# RL6955_IP_SVD register map
Vendor: Realtek
Registers are 32-bit, read-write, reset 0x0 unless marked. A register's access mark holds for its fields unless they carry their own. Offsets are from the block's base; [hi:lo] are bit positions; {n}, {i} and the like mark numbered series.

## UARTLOG_REG
Base 0x41005000
0x00 UART_DLL — UART divisor length register
  [7:0] baud — The low 8 bits of divisor coefficient (not used)
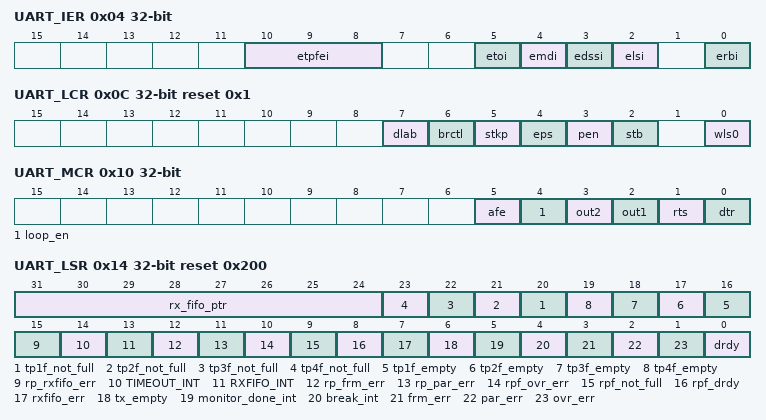
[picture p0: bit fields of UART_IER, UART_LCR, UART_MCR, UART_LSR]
0x04 UART_IER — UART interrupt enable register
  [10:8] etpfei — Tx Path FIFO Empty interrupt (ETPFEI) (Tx Path FIFO empty) enable control *000: All Tx Path FIFO empty interrupt disabled *001: Tx Path1 FIFO Empty interrupt enabled *010: Tx Path2 FIFO Empty interrupt enabled *011: Tx Path3 FIFO Empty interrupt enabled *100: Tx Path4 FIFO Empty interrupt enabled *Others: Reserved
  [5] etoi — Rx timeout interrupt (ETOI) enable
  [4] emdi — Rx path monitor done interrupt (EMDI) enable
  [3] edssi — Modem Status Interrupt (EDSSI) (modem status transition) enable
  [2] elsi — Receiver Line Status Interrupt (ELSI) (receiver line status) enable
  [0] erbi — Received Data Available Interrupt (ERBFI) (Rx trigger) enable
0x08 UART_IIR ro reset 0x1 — UART interrupt identification register
  [0] int_pend — Indicate if the interrupt is pending. *0: Pending, and the IIR contents may be used as a pointer to the appropriate interrupt service routine. *1: No interrupt is pending.
0x0C UART_LCR reset 0x1 — UART line control register
  [7] dlab — Divisor Latch Access bit, and control the accessibility of the DLL, DLM and IER registers * 0: The divisor latches not accessible; IER accessible * 1: The divisor latches accessible; DLL and DLM accessible Note: THR/RBR don't care the value of dlab bit
  [6] brctl — Break Control bit * 0: break signal disable * 1: break signal enable (logic '0')
  [5] stkp — Stick Parity bit * 0: Not stick parity, the parity type is ODD or EVEN (depending on eps) * 1: Stick parity, eps=1: low parity (1'b0); eps=0: high parity (1'b1)
  [4] eps — Even Parity select * 0: Odd parity, the number of Logic "1" is odd. * 1: Even parity, the number of Logic "1" is even.
  [3] pen — Parity Enable * 0: No parity bit * 1: Parity bit is generated on each outgoing character and is checked on each incoming one
  [2] stb — Stop bits length selection * 0: 1 stop bit * 1: 2 stop bits Note: The receiver always checks the first stop bit only.
  [0] wls0 — Word length selection * 0: 7 bits data * 1: 8 bits data
0x10 UART_MCR — UART modem control register
  [5] afe — Auto flow control enable
  [4] loop_en — LoopBack mode * 0: Normal operation mode * 1: Loopback mode
  [3] out2 — Auxiliary output 2 Bit[3] affects the OUT2_ output in a manner identical to that described above set to 0 In loopback mode, connected to Data Carrier Detect (DCD)
  [2] out1 — Auxiliary output 1 Bit3 affects the OUT1_ output in a manner identical to that described above set to 0 In loopback mode, connected to Ring Indicator (RI)
  [1] rts — Request to Send (RTS) signal control * 0: RTS is logic 1. * 1: RTS is logic 0. This bit controls the RTS_ output, Bit 1 affects the RTS_ output in a manner identical to that described above set to 0.
  [0] dtr — Data Terminal Ready (DTR) signal control * 0: DTR is logic 1. * 1: DTR is logic 0. This bit controls the DTR output.
0x14 UART_LSR ro reset 0x200 — UART line status register
  [31:24] rx_fifo_ptr — Data bytes count in the receive FIFO: the value of rx_fifo_ptr[7:0] indicates the data bytes number received in the FIFO.
  [n+19] tp{n}f_not_full (n=1..4) — Tx Path{n} FIFO not full indicator
  [n+15] tp{n}f_empty (n=1..4) — Tx Path{n} FIFO empty indicator
  [15] rp_rxfifo_err — Relay Path rx_error,only valid when the FCR[12] set to 1 * 0: Clear when the CPU reads the LSR, if there are no subsequent errors in the relay path FIFO * 1: Parity error, framing error or break indication in the relay path FIFO
  [14] TIMEOUT_INT — This bit is only set when Rx Timeout interrupt is enabled(ETOI is set) 1: at least one character in the FIFO but no character has been input to the FIFO or reading from it for the time duration, which depends on the value in register REG_RX_PATH_CTRL[31:16]
  [13] RXFIFO_INT — This bit is only set when Received Data Available Interrupt interrupt is enabled(ERBI is set) 1: FIFO Trigger level reached or Rx FIFO full
  [12] rp_frm_err — Relay Path Framing Error (FE) indicator * 0: No framing error in the current character * 1: The received character does not have a valid stop bit
  [11] rp_par_err — Relay Path Parity Error (PE) indicator * 0: No parity error in current character * 1: The received character does not have the correct parity bit
  [10] rpf_ovr_err — Relay Path FIFO Overrun Error (OE) indicator * 0: No Overrun state * 1: The transmission is continue although the Relay FIFO is full
  [9] rpf_not_full — Relay Path FIFO Not FULL (NF) indicator * 0: Relay path FIFO is full * 1: Relay path FIFO is not full
  [8] rpf_drdy — Relay Path FIFO Data Ready (DR) indicator * 0: No characters in the Relay Receiver FIFO * 1: At least one character has been received and transferred into the Relay path FIFO
  [7] rxfifo_err — Uart_rx_error, only valid when the FCR bit [0] set to 1 * 0: Clear when the CPU reads the LSR, if there are no subsequent errors in the FIFO * 1: Parity error, overrun error,framing error or break indication in the FIFO
  [6] tx_empty — TX fifo empty indicator
  [5] monitor_done_int — This bit is only set when Rx Path Monitor Done interrupt is enabled(EMDI is set) 1: Rx path monitor done
  [4] break_int — Break Interrupt (BI) indicator * 0: No break condition in the current character * 1: The received data input held in the Spacing ( logic 0) state is longer than a full word transmission time
  [3] frm_err — Framing Error (FE) indicator * 0: No framing error in the current character * 1: The received character does not have a valid stop bit
  [2] par_err — Parity Error (PE) indicator * 0: No parity error in current character * 1: The received character does not have the correct parity bit
  [1] ovr_err — Overrun Error (OE) indicator * 0: No Overrun state * 1: The transmission is continue although the Rx FIFO is full
  [0] drdy — Data Ready (DR) indicator * 0: No characters in the Receiver FIFO * 1: At least one character has been received and transferred into the FIFO
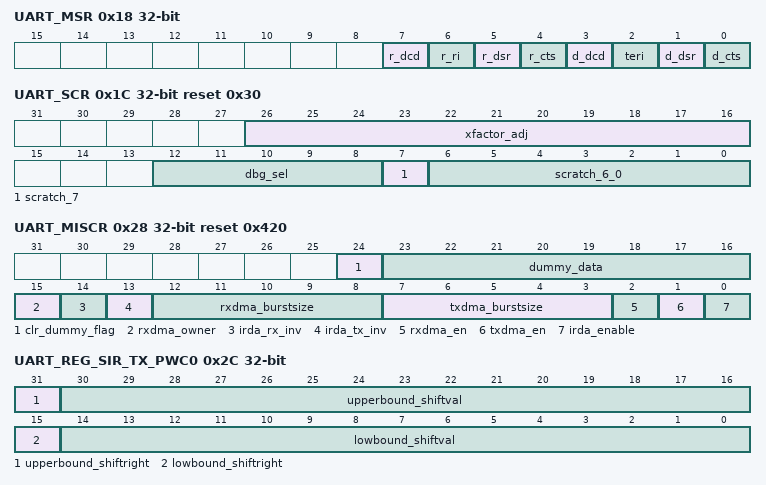
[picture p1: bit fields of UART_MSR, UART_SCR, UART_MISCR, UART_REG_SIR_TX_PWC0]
0x18 UART_MSR ro — UART modem status register
  [7] r_dcd — Complement of the DCD input or equals to Out2 in loopback mode.
  [6] r_ri — Complement of the RI input or equals to Out1 in loopback mode.
  [5] r_dsr — Complement of the DSR input or equals to DTR in loopback mode.
  [4] r_cts — Complement of the CTS input or equals to RTS in loopback mode.
  [3] d_dcd — Delta Data Carrier Detect (DDCD) indicator * 0: Otherwise * 1: The DCD line has changed its state
  [2] teri — Trailing Edge of Ring Indicator (TERI) detector * 0: Otherwise * 1: The RI line has changed its state from low to high state
  [1] d_dsr — Delta Data Set Ready (DDSR) indicator * 0: Otherwise * 1: The DSR line has changed its state
  [0] d_cts — Delta Clear to Send (DCTS) indicator * 0: Otherwise * 1: The CTS line has changed its state
0x1C UART_SCR reset 0x30 — UART scratch pad register
  [26:16] xfactor_adj — One factor of Baud rate calculation for Tx path
  [12:8] dbg_sel — Debug port selection
  [7] scratch_7 — clear Rx break signal interrupt status
  [6:0] scratch_6_0 — *Bit[6]: Rx break signal interrupt enable *Bit[5]: fl_set_bi_err *Bit[4]: fl_frame_err *Bit[3]: pin_lb_test *Bit[2:0]: reserved
0x20 UART_STSR reset 0x10470 — UART STS register
  [23:4] xfactor — Factor of Baud rate calculation for Tx path
0x24 UART_RBR ro — UART receiver buffer register
  [7:0] rxdatabit — Tx data bit 0~7 Note: Bit[0] is the least significant bit. It is the first bit serially received/transmitted.
0x28 UART_MISCR access per field reset 0x420 — UART MISC control register
  [24] clr_dummy_flag wo — Indicate the clearing of dummy data
  [23:16] dummy_data rw — Store dummy data, when UART is DMA flow controller, dummy data is padded for last RXDMA burst request
  [15] rxdma_owner rw — Indicate the DMA flow controller for UART Rx DMA1 * 0: GDMA * 1: UART, interrupt enable signal other than erpd should be masked
  [14] irda_rx_inv rw — irda_rx_i reverse input enable
  [13] irda_tx_inv rw — irda_tx_o reverse output enable
  [12:8] rxdma_burstsize rw — RXDMA burstsize, maximum value is 16
  [7:3] txdma_burstsize rw — TXDMA burstsize, maximum value is 16
  [2] rxdma_en rw — RXDMA enable, valid when dma_mode in FCR is 1'b1
  [1] txdma_en rw — TXDMA enable, valid when dma_mode in FCR is 1'b1
  [0] irda_enable rw — IrDA SIR mode enable * 0: UART mode only * 1: UART is co-work with IRDA SIR mode
0x2C UART_REG_SIR_TX_PWC0 — UART IRDA SIR Tx pulse width control 0 register
  [31] upperbound_shiftright — Indicate the shift type of SIR Tx pulse's right edge * 0: Shift left, minus offset value of upperbound_shiftval * 1: Shift right, plus offset value of upperbound_shiftval
  [30:16] upperbound_shiftval — The shift value of SIR Tx pulse's right edge
  [15] lowbound_shiftright — Indicate the shift type of SIR Tx pulse's left edge * 0: Shift left, minus offset value of lowbound_shiftval * 1: Shift right, plus offset value of lowbound_shiftval
  [14:0] lowbound_shiftval — The shift value of SIR Tx pulse's left edge
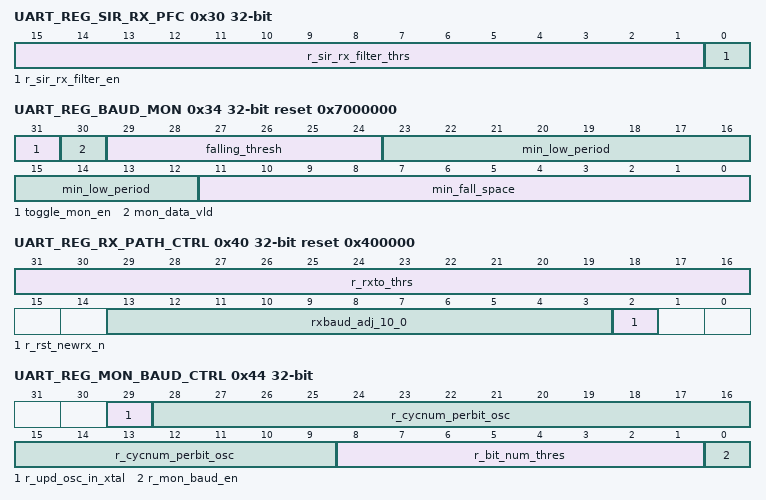
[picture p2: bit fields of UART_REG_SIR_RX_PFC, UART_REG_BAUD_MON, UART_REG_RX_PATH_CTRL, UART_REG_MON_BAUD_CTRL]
0x30 UART_REG_SIR_RX_PFC — UART IRDA SIR Rx pulse filter control register
  [15:1] r_sir_rx_filter_thrs — The threshold of SIR Rx filter. Rx pulse is valid only when Rx pulse width is larger than the threshold.
  [0] r_sir_rx_filter_en — IrDA SIR Rx filter enable
0x34 UART_REG_BAUD_MON access per field reset 0x7000000 — UART baud monitor register
  [31] toggle_mon_en rw — Toggle monitor enable
  [30] mon_data_vld ro — Indicate valid monitoring data
  [29:24] falling_thresh rw — Indicate the threshold of Rx data rising edge
  [23:12] min_low_period ro — Minimum space of consecutive logic "0" of Rx data
  [11:0] min_fall_space ro — Minimum space of adjacent falling edge of Rx data
0x3C UART_REG_DBG ro — UART debug register
  [31:0] dbg_uart — The output value of debug port, depend on dbg_sel value in SCR[2:0]
0x40 UART_REG_RX_PATH_CTRL reset 0x400000 — UART Rx path control register
  [31:16] r_rxto_thrs — Indicate the timeout threshold of Rx path, unit in one-bit time
  [13:3] rxbaud_adj_10_0 — One factor of Baud rate calculation for Rx path, similar with xfactor_adj
  [2] r_rst_newrx_n — Reset new Rx path, low active
0x44 UART_REG_MON_BAUD_CTRL — UART monitor baud rate control register
  [29] r_upd_osc_in_xtal — Update parameter r_cycnum_perbit_osc(during the update of parameter r_cycnum_perbit_xtal) enable
  [28:9] r_cycnum_perbit_osc — Indicate the average OSC clock cycle number of one bit, for Rx path OSC clock Note: Sortware sets the initial value; hardware updates it depending on the monitor result.
  [8:1] r_bit_num_thres — Indicate the bit number threshold of one monitor period, max value is 127.
  [0] r_mon_baud_en — Monitor Rx baud enable
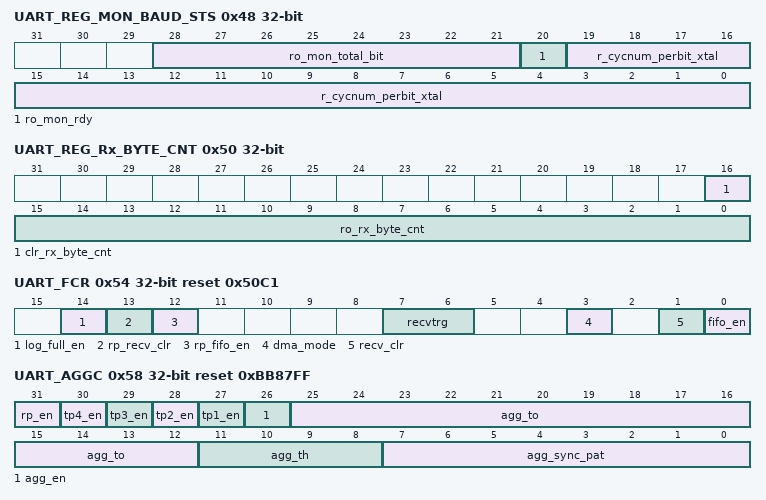
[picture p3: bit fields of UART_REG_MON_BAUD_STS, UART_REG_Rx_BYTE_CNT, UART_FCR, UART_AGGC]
0x48 UART_REG_MON_BAUD_STS access per field — UART monitor baud rate status register
  [28:21] ro_mon_total_bit ro — Indicate the number of bits actually monitored
  [20] ro_mon_rdy ro — Indicate the finish of calculation of actual cycle number per bit. It's cleared when r_mon_baud_en is 0.
  [19:0] r_cycnum_perbit_xtal rw — Indicate the fractional xtal clock cycle number of one bit, for Rx path xtal clk Note: Sortware sets the initial value; hardware updates it depending on the monitor result.
0x4C UART_REG_MON_CYC_NUM ro — UART monitored cycle number register
  [27:0] ro_mon_total_cycle — Indicate the number of clock cycle actually monitored
0x50 UART_REG_Rx_BYTE_CNT access per field — UART Rx data byte count register
  [16] clr_rx_byte_cnt wo — Write 1 to clear ro_rx_byte_cnt
  [15:0] ro_rx_byte_cnt ro — Count the byte number of data read from rxfifo
0x54 UART_FCR access per field reset 0x50C1 — UART FIFO control register
  [14] log_full_en rw — Function enable: when disable agg, and log byte is 0x0a or this fifo is empty timeout, switch tx fifo
  [13] rp_recv_clr wo — Clear Relay Path receiving
  [12] rp_fifo_en rw — Error report of Relay Path RCVR FIFO field enable,
  [7:6] recvtrg rw — Define the 32-entry Receiver FIFO Interrupt trigger level (0~31 bytes) * 00: 1 byte * 01: FIFO_DEPTH/4 * 10: FIFO_DEPTH/2 * 11: FIFO_DEPTH-2
  [3] dma_mode rw — Support DMA mode (cooperating with DW DDMA in the data path)
  [1] recv_clr wo — Clear receiving
  [0] fifo_en rw — Error report of RCVR FIFO field enable
0x58 UART_AGGC reset 0xBB87FF — UART AGG control register
  [31] rp_en — Relay Rx Path enable *0: Disable *1: Enable
  [n+26] tp{n}_en (n=1..4) — Tx Path{n} enable *0: Disable *1: Enable
  [26] agg_en — Tx AGG function enable
  [25:12] agg_to — AGG timeout Data should be sent from log FIFO to tx_fifo if idle time > AGG timeout, even if there is just only one byte in log FIFO of the path. when agg_en=0: Unit is 25ns. when agg_en=1: Unit is one baudrate period of loguart Tx, default is 1ms if Tx baudrate is 3Mbps.
  [11:8] agg_th — AGG threshold 4'0000: 1 4'0111: 8 Numbers above 4'0111 are reserved.
  [7:0] agg_sync_pat — AGG packet Start
{0x5C+4i} UART_THR{i} wo (i=0..3) — UART transmitter holding register {i}
  [7:0] tx{i}databit — Tx data bit 0~7 Note: Bit 0 is the least significant bit. It is the first bit serially received/transmitted
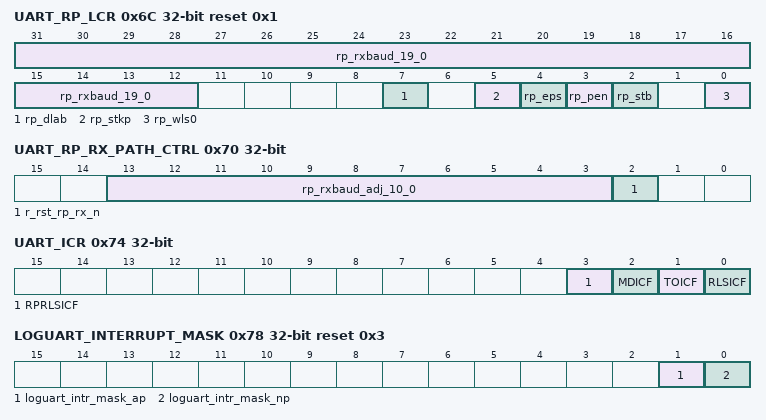
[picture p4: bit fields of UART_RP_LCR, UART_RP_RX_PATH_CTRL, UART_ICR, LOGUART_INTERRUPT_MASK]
0x6C UART_RP_LCR reset 0x1 — UART Relay Rx Path line control register
  [31:12] rp_rxbaud_19_0 — Factor of Baud rate calculation for Relay path
  [7] rp_dlab — Divisor Latch Access bit, and control the accessibility of the DLL, DLM and IER registers * 0: The divisor latches not accessible; IER accessible * 1: The divisor latches accessible; DLL and DLM accessible Note: THR/RBR don not care the value of dlab bit.
  [5] rp_stkp — Stick Parity bit * 0: Not stick parity, the parity type is ODD or EVEN (depend on eps) * 1: Stick parity, eps=1: low parity (1'b0); eps=0: high parity (1'b1)
  [4] rp_eps — Even Parity select * 0: Odd parity, the number of Logic "1" is odd. * 1: Even parity, the number of Logic "1" is even.
  [3] rp_pen — Parity Enable * 0: No parity bit * 1: Parity bit is generated on each outgoing character and is checked on each incoming one.
  [2] rp_stb — Stop bits length selection * 0: 1 stop bit * 1: 2 stop bits Note: the receiver always checks the first stop bit only.
  [0] rp_wls0 — Word length selection * 0: 7 bits data * 1: 8 bits data
0x70 UART_RP_RX_PATH_CTRL — UART Relay Rx path control register
  [13:3] rp_rxbaud_adj_10_0 — One factor of Baud rate calculation for Relay path, similar with xfactor_adj
  [2] r_rst_rp_rx_n — Reset Relay Rx path, low active
0x74 UART_ICR wo — UART interrupt clear register
  [3] RPRLSICF — Relay Path Receiver Line Statue Interrupt Clear Flag Writing 1 to this bit clears relay path's PARITY_ERR, OVERRUN_ERR, FRAMING_ERR and RXFIFO_ERR in the USART_LSR register.
  [2] MDICF — Monitor done clear flag
  [1] TOICF — Timeout Interrupt Clear Flag
  [0] RLSICF — Receiver Line Statue Interrupt Clear Flag Writing 1 to this bit clears PARITY_ERR, OVERRUN_ERR, FRAMING_ERR, BREAK_ERR_INT and RXFIFO_ERR in the USART_LSR register.
0x78 LOGUART_INTERRUPT_MASK reset 0x3
  [1] loguart_intr_mask_ap — Mask loguart interrupt to AP 1:unmask 0:mask
  [0] loguart_intr_mask_np — Mask loguart interrupt to NP 1:unmask 0:mask
0xF0 LOGUART_DUMMY ro
  [15:0] dummy — rsvd for hw
